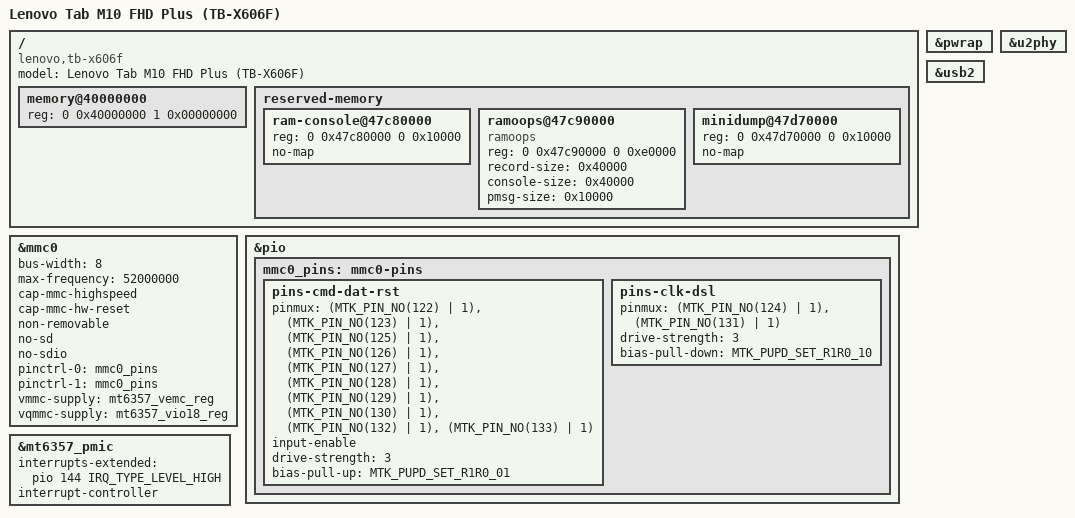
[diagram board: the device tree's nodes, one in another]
// SPDX-License-Identifier: (GPL-2.0 OR MIT)
/* Lenovo Tab M10 FHD Plus (TB-X606F, achilles6_row_wifi) */

/dts-v1/;

#include "mt6765.dtsi"
#include "mt6357.dtsi"

/ {
	model = "Lenovo Tab M10 FHD Plus (TB-X606F)";
	compatible = "lenovo,tb-x606f", "mediatek,mt6765";

	memory@40000000 {
		device_type = "memory";
		reg = <0 0x40000000 1 0x00000000>;
	};

	reserved-memory {
		#address-cells = <2>;
		#size-cells = <2>;
		ranges;

		ram-console@47c80000 {
			reg = <0 0x47c80000 0 0x10000>;
			no-map;
		};

		ramoops@47c90000 {
			compatible = "ramoops";
			reg = <0 0x47c90000 0 0xe0000>;
			record-size = <0x40000>;
			console-size = <0x40000>;
			pmsg-size = <0x10000>;
		};

		minidump@47d70000 {
			reg = <0 0x47d70000 0 0x10000>;
			no-map;
		};
	};
};

&mmc0 {
	bus-width = <8>;
	max-frequency = <52000000>;
	cap-mmc-highspeed;
	cap-mmc-hw-reset;
	non-removable;
	no-sd;
	no-sdio;
	pinctrl-names = "default", "state_uhs";
	pinctrl-0 = <&mmc0_pins>;
	pinctrl-1 = <&mmc0_pins>;
	vmmc-supply = <&mt6357_vemc_reg>;
	vqmmc-supply = <&mt6357_vio18_reg>;
	status = "okay";
};

&pio {
	mmc0_pins: mmc0-pins {
		pins-cmd-dat-rst {
			pinmux = <(MTK_PIN_NO(122) | 1)>,
				 <(MTK_PIN_NO(123) | 1)>,
				 <(MTK_PIN_NO(125) | 1)>,
				 <(MTK_PIN_NO(126) | 1)>,
				 <(MTK_PIN_NO(127) | 1)>,
				 <(MTK_PIN_NO(128) | 1)>,
				 <(MTK_PIN_NO(129) | 1)>,
				 <(MTK_PIN_NO(130) | 1)>,
				 <(MTK_PIN_NO(132) | 1)>,
				 <(MTK_PIN_NO(133) | 1)>;
			input-enable;
			drive-strength = <3>;
			bias-pull-up = <MTK_PUPD_SET_R1R0_01>;
		};

		pins-clk-dsl {
			pinmux = <(MTK_PIN_NO(124) | 1)>,
				 <(MTK_PIN_NO(131) | 1)>;
			drive-strength = <3>;
			bias-pull-down = <MTK_PUPD_SET_R1R0_10>;
		};
	};
};

&mt6357_pmic {
	interrupts-extended = <&pio 144 IRQ_TYPE_LEVEL_HIGH>;
	interrupt-controller;
	#interrupt-cells = <2>;
};

&pwrap {
	status = "okay";
};

&u2phy {
	status = "okay";
};

&usb2 {
	status = "okay";
};
